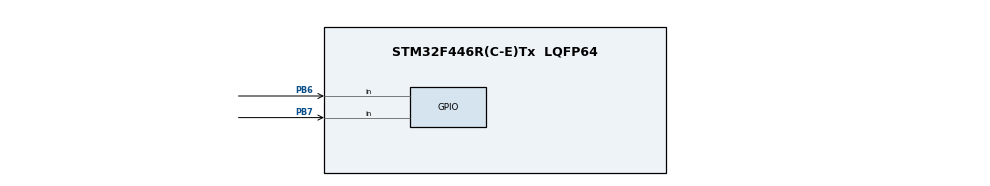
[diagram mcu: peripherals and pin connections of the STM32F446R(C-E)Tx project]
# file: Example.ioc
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Mcu.Family=STM32F4
Mcu.Name=STM32F446R(C-E)Tx
Mcu.Package=LQFP64
NVIC.PriorityGroup=NVIC_PRIORITYGROUP_4
NVIC.TIM1_UP_TIM10_IRQn=true\:0\:0\:false\:false\:true\:true\:true\:true
PB6.GPIO_PuPd=GPIO_PULLUP
PB6.Signal=GPIO_Input
PB7.GPIO_PuPd=GPIO_PULLUP
PB7.Signal=GPIO_Input
ProjectManager.HeapSize=0x200
ProjectManager.StackSize=0x400
ProjectManager.TargetToolchain=STM32CubeIDE
RCC.CortexFreq_Value=16000000
RCC.USBFreq_Value=96000000
RCC.VCOOutputFreq_Value=192000000
TIM10.Channel=TIM_CHANNEL_1
TIM10.Period=10000
TIM10.Prescaler=8399
VP_TIM10_VS_ClockSourceINT.Mode=Enable_Timer
VP_TIM10_VS_no_output1.Mode=Output Compare1 No Output
board=custom

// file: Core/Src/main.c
/* USER CODE BEGIN Header */
/**
  ******************************************************************************
  * @file           : main.c
  * @brief          : Main program body
  ******************************************************************************
  * @attention
  *
  * salut supp yolo
  *
  * salut lol
  *
  * Copyright (c) 2023 STMicroelectronics.
  * All rights reserved.
  *
  * This software is licensed under terms that can be found in the LICENSE file
  * in the root directory of this software component.
  * If no LICENSE file comes with this software, it is provided AS-IS.
  *
  ******************************************************************************
  */
/* USER CODE END Header */
#include "main.h"

/* USER CODE BEGIN Includes */
struct type_code_secret{
	int structure_valide;
} maStructure;
/* USER CODE END Includes */

TIM_HandleTypeDef htim10;

void SystemClock_Config(void);
static void MX_GPIO_Init(void);
static void MX_TIM10_Init(void);

/* USER CODE BEGIN 0 */
FLASH_EraseInitTypeDef S_FLASH_ERASE;
/* USER CODE END 0 */

int main(void)
{

  /* MCU Configuration--------------------------------------------------------*/

  /* Reset of all peripherals, Initializes the Flash interface and the Systick. */
  HAL_Init();

  /* Configure the system clock */
  SystemClock_Config();

  /* Initialize all configured peripherals */
  MX_GPIO_Init();
  MX_TIM10_Init();

  /* Infinite loop */
  while (1)
  {

  }
}

void SystemClock_Config(void)
{
  RCC_OscInitTypeDef RCC_OscInitStruct = {0};
  RCC_ClkInitTypeDef RCC_ClkInitStruct = {0};

  /** Configure the main internal regulator output voltage
  */
  __HAL_RCC_PWR_CLK_ENABLE();
  __HAL_PWR_VOLTAGESCALING_CONFIG(PWR_REGULATOR_VOLTAGE_SCALE3);

  /** Initializes the RCC Oscillators according to the specified parameters
  * in the RCC_OscInitTypeDef structure.
  */
  RCC_OscInitStruct.OscillatorType = RCC_OSCILLATORTYPE_HSI;
  RCC_OscInitStruct.HSIState = RCC_HSI_ON;
  RCC_OscInitStruct.HSICalibrationValue = RCC_HSICALIBRATION_DEFAULT;
  RCC_OscInitStruct.PLL.PLLState = RCC_PLL_NONE;
  if (HAL_RCC_OscConfig(&RCC_OscInitStruct) != HAL_OK)
  {
    Error_Handler();
  }

  /** Initializes the CPU, AHB and APB buses clocks
  */
  RCC_ClkInitStruct.ClockType = RCC_CLOCKTYPE_HCLK|RCC_CLOCKTYPE_SYSCLK
                              |RCC_CLOCKTYPE_PCLK1|RCC_CLOCKTYPE_PCLK2;
  RCC_ClkInitStruct.SYSCLKSource = RCC_SYSCLKSOURCE_HSI;
  RCC_ClkInitStruct.AHBCLKDivider = RCC_SYSCLK_DIV1;
  RCC_ClkInitStruct.APB1CLKDivider = RCC_HCLK_DIV1;
  RCC_ClkInitStruct.APB2CLKDivider = RCC_HCLK_DIV1;

  if (HAL_RCC_ClockConfig(&RCC_ClkInitStruct, FLASH_LATENCY_0) != HAL_OK)
  {
    Error_Handler();
  }
}

static void MX_TIM10_Init(void)
{

  TIM_OC_InitTypeDef sConfigOC = {0};

  htim10.Instance = TIM10;
  htim10.Init.Prescaler = 8399;
  htim10.Init.CounterMode = TIM_COUNTERMODE_UP;
  htim10.Init.Period = 10000;
  htim10.Init.ClockDivision = TIM_CLOCKDIVISION_DIV1;
  htim10.Init.AutoReloadPreload = TIM_AUTORELOAD_PRELOAD_DISABLE;
  if (HAL_TIM_Base_Init(&htim10) != HAL_OK)
  {
    Error_Handler();
  }
  if (HAL_TIM_OC_Init(&htim10) != HAL_OK)
  {
    Error_Handler();
  }
  sConfigOC.OCMode = TIM_OCMODE_TIMING;
  sConfigOC.Pulse = 0;
  sConfigOC.OCPolarity = TIM_OCPOLARITY_HIGH;
  sConfigOC.OCFastMode = TIM_OCFAST_DISABLE;
  if (HAL_TIM_OC_ConfigChannel(&htim10, &sConfigOC, TIM_CHANNEL_1) != HAL_OK)
  {
    Error_Handler();
  }

}

static void MX_GPIO_Init(void)
{
  GPIO_InitTypeDef GPIO_InitStruct = {0};

  /* GPIO Ports Clock Enable */
  __HAL_RCC_GPIOB_CLK_ENABLE();

  /*Configure GPIO pins : PB6 PB7 */
  GPIO_InitStruct.Pin = GPIO_PIN_6|GPIO_PIN_7;
  GPIO_InitStruct.Mode = GPIO_MODE_INPUT;
  GPIO_InitStruct.Pull = GPIO_PULLUP;
  HAL_GPIO_Init(GPIOB, &GPIO_InitStruct);

}

/* USER CODE BEGIN 4 */
void HAL_TIM_PeriodElapsedCallback(TIM_HandleTypeDef *htim){
	if (htim == &htim10){
		// Programme ici
	}
}
/* USER CODE END 4 */

void Error_Handler(void)
{
  __disable_irq();
  while (1)
  {
  }
}
